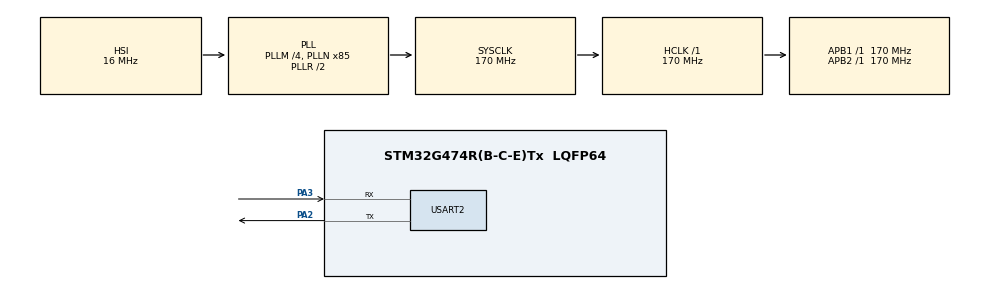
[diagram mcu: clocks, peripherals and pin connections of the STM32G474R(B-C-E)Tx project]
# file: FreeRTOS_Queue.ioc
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FREERTOS.Queues01=SharedQueue,10,SensorData_t,0,Dynamic,NULL,NULL
FREERTOS.Tasks01=TemperatureTask,24,128,StartTemperatureTask,Default,NULL,Dynamic,NULL,NULL;UARTTask,16,256,StartUARTTask,Default,NULL,Dynamic,NULL,NULL;HumidityTask,24,128,StartHumidityTask,Default,NULL,Dynamic,NULL,NULL;PressureTask,24,128,StartPressureTask,Default,NULL,Dynamic,NULL,NULL
FREERTOS.configTOTAL_HEAP_SIZE=8192
Mcu.Family=STM32G4
Mcu.Name=STM32G474R(B-C-E)Tx
Mcu.Package=LQFP64
NVIC.PriorityGroup=NVIC_PRIORITYGROUP_4
NVIC.TIM4_IRQn=true\:15\:0\:false\:false\:true\:false\:false\:true\:true
NVIC.TimeBase=TIM4_IRQn
NVIC.TimeBaseIP=TIM4
PA13.Mode=Serial_Wire
PA13.Signal=SYS_JTMS-SWDIO
PA14.Mode=Serial_Wire
PA14.Signal=SYS_JTCK-SWCLK
PA2.Mode=Asynchronous
PA2.Signal=USART2_TX
PA2.TagName=VCP_TX
PA3.Mode=Asynchronous
PA3.Signal=USART2_RX
PA3.TagName=VCP_RX
PA5.TagName=LD2
PC13.TagName=B1
ProjectManager.HeapSize=0x200
ProjectManager.StackSize=0x400
ProjectManager.TargetToolchain=STM32CubeIDE
RCC.ADC12Freq_Value=170000000
RCC.ADC345Freq_Value=170000000
RCC.AHBFreq_Value=170000000
RCC.APB1Freq_Value=170000000
RCC.APB1TimFreq_Value=170000000
RCC.APB2Freq_Value=170000000
RCC.APB2TimFreq_Value=170000000
RCC.CortexFreq_Value=170000000
RCC.EXTERNAL_CLOCK_VALUE=12288000
RCC.HCLKFreq_Value=170000000
RCC.HSE_VALUE=24000000
RCC.HSI48_VALUE=48000000
RCC.HSI_VALUE=16000000
RCC.LSE_VALUE=32768
RCC.PLLM=RCC_PLLM_DIV4
RCC.PLLN=85
RCC.RTCClockSelection=RCC_RTCCLKSOURCE_LSE
RCC.SYSCLKFreq_VALUE=170000000
RCC.SYSCLKSource=RCC_SYSCLKSOURCE_PLLCLK
RCC.USBFreq_Value=170000000
RCC.VCOOutputFreq_Value=340000000
USART2.VirtualMode-Asynchronous=VM_ASYNC
VP_FREERTOS_VS_CMSIS_V2.Mode=CMSIS_V2
VP_SYS_VS_DBSignals.Mode=DisableDeadBatterySignals
VP_SYS_VS_tim4.Mode=TIM4
board=NUCLEO-G474RE

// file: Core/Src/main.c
/* USER CODE BEGIN Header */
/**
  ******************************************************************************
  * @file           : main.c
  * @brief          : Main program body
  ******************************************************************************
  * @attention
  *
  * Copyright (c) 2026 STMicroelectronics.
  * All rights reserved.
  *
  * This software is licensed under terms that can be found in the LICENSE file
  * in the root directory of this software component.
  * If no LICENSE file comes with this software, it is provided AS-IS.
  *
  ******************************************************************************
  */
/* USER CODE END Header */
#include "main.h"
#include "cmsis_os.h"

/* USER CODE BEGIN Includes */
#include <string.h>
#include <stdio.h>
/* USER CODE END Includes */

/* USER CODE BEGIN PTD */
typedef struct
{
    uint8_t sensorID;
    uint32_t value;

} SensorData_t;
/* USER CODE END PTD */

UART_HandleTypeDef huart2;

/* Definitions for TemperatureTask */
osThreadId_t TemperatureTaskHandle;
const osThreadAttr_t TemperatureTask_attributes = {
  .name = "TemperatureTask",
  .priority = (osPriority_t) osPriorityNormal,
  .stack_size = 128 * 4
};
/* Definitions for UARTTask */
osThreadId_t UARTTaskHandle;
const osThreadAttr_t UARTTask_attributes = {
  .name = "UARTTask",
  .priority = (osPriority_t) osPriorityBelowNormal,
  .stack_size = 256 * 4
};
/* Definitions for HumidityTask */
osThreadId_t HumidityTaskHandle;
const osThreadAttr_t HumidityTask_attributes = {
  .name = "HumidityTask",
  .priority = (osPriority_t) osPriorityNormal,
  .stack_size = 128 * 4
};
/* Definitions for PressureTask */
osThreadId_t PressureTaskHandle;
const osThreadAttr_t PressureTask_attributes = {
  .name = "PressureTask",
  .priority = (osPriority_t) osPriorityNormal,
  .stack_size = 128 * 4
};
/* Definitions for SharedQueue */
osMessageQueueId_t SharedQueueHandle;
const osMessageQueueAttr_t SharedQueue_attributes = {
  .name = "SharedQueue"
};

void SystemClock_Config(void);
static void MX_GPIO_Init(void);
static void MX_USART2_UART_Init(void);
void StartTemperatureTask(void *argument);
void StartUARTTask(void *argument);
void StartHumidityTask(void *argument);
void StartPressureTask(void *argument);

/* USER CODE BEGIN 0 */
void uart_print(char *msg)
{
    HAL_UART_Transmit(&huart2, (uint8_t*)msg, strlen(msg), HAL_MAX_DELAY);
}
/* USER CODE END 0 */

int main(void)
{

  /* MCU Configuration--------------------------------------------------------*/

  /* Reset of all peripherals, Initializes the Flash interface and the Systick. */
  HAL_Init();

  /* Configure the system clock */
  SystemClock_Config();

  /* Initialize all configured peripherals */
  MX_GPIO_Init();
  MX_USART2_UART_Init();

  /* Init scheduler */
  osKernelInitialize();

  /* Create the queue(s) */
  /* creation of SharedQueue */
  SharedQueueHandle = osMessageQueueNew (10, sizeof(SensorData_t), &SharedQueue_attributes);

  /* Create the thread(s) */
  /* creation of TemperatureTask */
  TemperatureTaskHandle = osThreadNew(StartTemperatureTask, NULL, &TemperatureTask_attributes);

  /* creation of UARTTask */
  UARTTaskHandle = osThreadNew(StartUARTTask, NULL, &UARTTask_attributes);

  /* creation of HumidityTask */
  HumidityTaskHandle = osThreadNew(StartHumidityTask, NULL, &HumidityTask_attributes);

  /* creation of PressureTask */
  PressureTaskHandle = osThreadNew(StartPressureTask, NULL, &PressureTask_attributes);

  /* Start scheduler */
  osKernelStart();

  /* We should never get here as control is now taken by the scheduler */

  /* Infinite loop */
  while (1)
  {

  }
}

void SystemClock_Config(void)
{
  RCC_OscInitTypeDef RCC_OscInitStruct = {0};
  RCC_ClkInitTypeDef RCC_ClkInitStruct = {0};

  /** Configure the main internal regulator output voltage
  */
  HAL_PWREx_ControlVoltageScaling(PWR_REGULATOR_VOLTAGE_SCALE1_BOOST);

  /** Initializes the RCC Oscillators according to the specified parameters
  * in the RCC_OscInitTypeDef structure.
  */
  RCC_OscInitStruct.OscillatorType = RCC_OSCILLATORTYPE_HSI;
  RCC_OscInitStruct.HSIState = RCC_HSI_ON;
  RCC_OscInitStruct.HSICalibrationValue = RCC_HSICALIBRATION_DEFAULT;
  RCC_OscInitStruct.PLL.PLLState = RCC_PLL_ON;
  RCC_OscInitStruct.PLL.PLLSource = RCC_PLLSOURCE_HSI;
  RCC_OscInitStruct.PLL.PLLM = RCC_PLLM_DIV4;
  RCC_OscInitStruct.PLL.PLLN = 85;
  RCC_OscInitStruct.PLL.PLLP = RCC_PLLP_DIV2;
  RCC_OscInitStruct.PLL.PLLQ = RCC_PLLQ_DIV2;
  RCC_OscInitStruct.PLL.PLLR = RCC_PLLR_DIV2;
  if (HAL_RCC_OscConfig(&RCC_OscInitStruct) != HAL_OK)
  {
    Error_Handler();
  }

  /** Initializes the CPU, AHB and APB buses clocks
  */
  RCC_ClkInitStruct.ClockType = RCC_CLOCKTYPE_HCLK|RCC_CLOCKTYPE_SYSCLK
                              |RCC_CLOCKTYPE_PCLK1|RCC_CLOCKTYPE_PCLK2;
  RCC_ClkInitStruct.SYSCLKSource = RCC_SYSCLKSOURCE_PLLCLK;
  RCC_ClkInitStruct.AHBCLKDivider = RCC_SYSCLK_DIV1;
  RCC_ClkInitStruct.APB1CLKDivider = RCC_HCLK_DIV1;
  RCC_ClkInitStruct.APB2CLKDivider = RCC_HCLK_DIV1;

  if (HAL_RCC_ClockConfig(&RCC_ClkInitStruct, FLASH_LATENCY_4) != HAL_OK)
  {
    Error_Handler();
  }
}

static void MX_USART2_UART_Init(void)
{

  huart2.Instance = USART2;
  huart2.Init.BaudRate = 115200;
  huart2.Init.WordLength = UART_WORDLENGTH_8B;
  huart2.Init.StopBits = UART_STOPBITS_1;
  huart2.Init.Parity = UART_PARITY_NONE;
  huart2.Init.Mode = UART_MODE_TX_RX;
  huart2.Init.HwFlowCtl = UART_HWCONTROL_NONE;
  huart2.Init.OverSampling = UART_OVERSAMPLING_16;
  huart2.Init.OneBitSampling = UART_ONE_BIT_SAMPLE_DISABLE;
  huart2.Init.ClockPrescaler = UART_PRESCALER_DIV1;
  huart2.AdvancedInit.AdvFeatureInit = UART_ADVFEATURE_NO_INIT;
  if (HAL_UART_Init(&huart2) != HAL_OK)
  {
    Error_Handler();
  }
  if (HAL_UARTEx_SetTxFifoThreshold(&huart2, UART_TXFIFO_THRESHOLD_1_8) != HAL_OK)
  {
    Error_Handler();
  }
  if (HAL_UARTEx_SetRxFifoThreshold(&huart2, UART_RXFIFO_THRESHOLD_1_8) != HAL_OK)
  {
    Error_Handler();
  }
  if (HAL_UARTEx_DisableFifoMode(&huart2) != HAL_OK)
  {
    Error_Handler();
  }

}

static void MX_GPIO_Init(void)
{

  /* GPIO Ports Clock Enable */
  __HAL_RCC_GPIOA_CLK_ENABLE();

}

void StartTemperatureTask(void *argument)
{
  /* USER CODE BEGIN 5 */
	SensorData_t sensorData;

	sensorData.sensorID = 1;

	sensorData.value = 25;
  /* Infinite loop */
  for(;;)
  {
	  sensorData.value++;

	  if(sensorData.value > 40)
	  {
		  sensorData.value = 25;
	  }

	  osMessageQueuePut(SharedQueueHandle, &sensorData, 0, osWaitForever);
      osDelay(1000);
  }
  /* USER CODE END 5 */
}

void StartUARTTask(void *argument)
{
  /* USER CODE BEGIN StartUARTTask */
	SensorData_t receivedData;
	char msg[100];
  /* Infinite loop */
  for(;;)
  {
	  if(osMessageQueueGet(SharedQueueHandle, &receivedData, NULL, osWaitForever) == osOK)
	  {
		  switch(receivedData.sensorID)
		  {
		  	  case 1:
		  		sprintf(msg, "Temperature = %lu\r\n", receivedData.value);
		  		break;

		  	  case 2:
			  		sprintf(msg, "Humidity = %lu\r\n", receivedData.value);
			  		break;

		  	  case 3:
			  		sprintf(msg, "Pressure = %lu\r\n", receivedData.value);
			  		break;

		  	  default:
			  		sprintf(msg, "Unknown Sensor\r\n");
			  		break;
		  }

		  uart_print(msg);
	  }
  }
  /* USER CODE END StartUARTTask */
}

void StartHumidityTask(void *argument)
{
  /* USER CODE BEGIN StartHumidityTask */
    SensorData_t sensorData;

    sensorData.sensorID = 2;

    sensorData.value = 50;
  /* Infinite loop */
  for(;;)
  {
	  sensorData.value++;
	  if(sensorData.value > 80)
	  {
		  sensorData.value = 50;
	  }

	  osMessageQueuePut(SharedQueueHandle, &sensorData, 0, osWaitForever);
	  osDelay(1500);
  }
  /* USER CODE END StartHumidityTask */
}

void StartPressureTask(void *argument)
{
  /* USER CODE BEGIN StartPressureTask */
	SensorData_t sensorData;

	sensorData.sensorID = 3;

	sensorData.value = 1000;
  /* Infinite loop */
  for(;;)
  {
	  sensorData.value++;

	  if(sensorData.value > 1020)
	  {
		  sensorData.value = 1000;
	  }

	  osMessageQueuePut(SharedQueueHandle, &sensorData, 0, osWaitForever);
      osDelay(2000);
  }
  /* USER CODE END StartPressureTask */
}

void HAL_TIM_PeriodElapsedCallback(TIM_HandleTypeDef *htim)
{
  if (htim->Instance == TIM4)
  {
    HAL_IncTick();
  }
}

void Error_Handler(void)
{
  __disable_irq();
  while (1)
  {
  }
}
